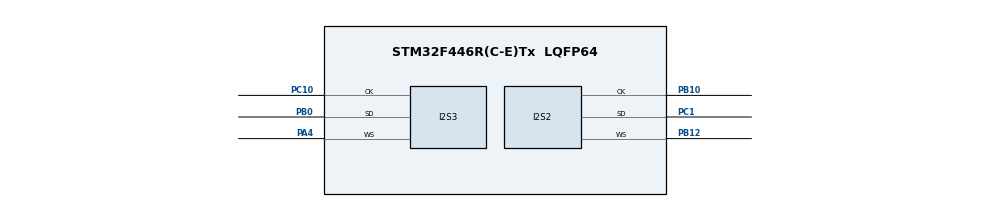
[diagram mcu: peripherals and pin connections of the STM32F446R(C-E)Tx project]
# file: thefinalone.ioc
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Dma.Request0=SPI2_TX
Dma.Request1=SPI3_RX
Dma.SPI2_TX.0.Direction=DMA_MEMORY_TO_PERIPH
Dma.SPI2_TX.0.FIFOMode=DMA_FIFOMODE_DISABLE
Dma.SPI2_TX.0.Instance=DMA1_Stream4
Dma.SPI2_TX.0.MemDataAlignment=DMA_MDATAALIGN_BYTE
Dma.SPI2_TX.0.MemInc=DMA_MINC_ENABLE
Dma.SPI2_TX.0.Mode=DMA_CIRCULAR
Dma.SPI2_TX.0.PeriphDataAlignment=DMA_PDATAALIGN_BYTE
Dma.SPI2_TX.0.PeriphInc=DMA_PINC_DISABLE
Dma.SPI2_TX.0.Priority=DMA_PRIORITY_HIGH
Dma.SPI3_RX.1.Direction=DMA_PERIPH_TO_MEMORY
Dma.SPI3_RX.1.FIFOMode=DMA_FIFOMODE_DISABLE
Dma.SPI3_RX.1.Instance=DMA1_Stream2
Dma.SPI3_RX.1.MemDataAlignment=DMA_MDATAALIGN_BYTE
Dma.SPI3_RX.1.MemInc=DMA_MINC_ENABLE
Dma.SPI3_RX.1.Mode=DMA_CIRCULAR
Dma.SPI3_RX.1.PeriphDataAlignment=DMA_PDATAALIGN_BYTE
Dma.SPI3_RX.1.PeriphInc=DMA_PINC_DISABLE
Dma.SPI3_RX.1.Priority=DMA_PRIORITY_HIGH
I2S2.AudioFreq=I2S_AUDIOFREQ_16K
I2S2.DataFormat=I2S_DATAFORMAT_24B
I2S2.ErrorAudioFreq=-0.26 %
I2S2.FullDuplexMode=I2S_FULLDUPLEXMODE_DISABLE
I2S2.Instance=SPI$Index
I2S2.RealAudioFreq=15.957 KHz
I2S2.Standard=I2S_STANDARD_PHILIPS
I2S2.VirtualMode=I2S_MODE_MASTER
I2S3.AudioFreq=I2S_AUDIOFREQ_16K
I2S3.ClockSource-Half_Duplex_Master=I2S_CLOCK_PLL
I2S3.DataFormat=I2S_DATAFORMAT_24B
I2S3.ErrorAudioFreq=-0.26 %
I2S3.FullDuplexMode=I2S_FULLDUPLEXMODE_DISABLE
I2S3.Instance=SPI$Index
I2S3.Mode=I2S_MODE_MASTER_RX
I2S3.RealAudioFreq=15.957 KHz
I2S3.Standard=I2S_STANDARD_PHILIPS
I2S3.VirtualMode=I2S_MODE_MASTER
Mcu.Family=STM32F4
Mcu.Name=STM32F446R(C-E)Tx
Mcu.Package=LQFP64
NVIC.DMA1_Stream2_IRQn=true\:0\:0\:false\:false\:true\:false\:true\:true
NVIC.DMA1_Stream4_IRQn=true\:0\:0\:false\:false\:true\:false\:true\:true
NVIC.PriorityGroup=NVIC_PRIORITYGROUP_4
PA0-WKUP.Signal=UART4_TX
PA1.Signal=UART4_RX
PA13.Mode=JTAG_5_pins
PA13.Signal=SYS_JTMS-SWDIO
PA14.Mode=JTAG_5_pins
PA14.Signal=SYS_JTCK-SWCLK
PA15.Mode=JTAG_5_pins
PA15.Signal=SYS_JTDI
PA4.Mode=Half_Duplex_Master
PA4.Signal=I2S3_WS
PB0.Mode=Half_Duplex_Master
PB0.Signal=I2S3_SD
PB10.Mode=Half_Duplex_Master
PB10.Signal=I2S2_CK
PB12.Mode=Half_Duplex_Master
PB12.Signal=I2S2_WS
PB3.Mode=JTAG_5_pins
PB3.Signal=SYS_JTDO-SWO
PB4.Mode=JTAG_5_pins
PB4.Signal=SYS_JTRST
PC1.Mode=Half_Duplex_Master
PC1.Signal=I2S2_SD
PC10.Mode=Half_Duplex_Master
PC10.Signal=I2S3_CK
ProjectManager.HeapSize=0x200
ProjectManager.StackSize=0x400
ProjectManager.TargetToolchain=STM32CubeIDE
RCC.CortexFreq_Value=16000000
RCC.HSE_VALUE=25000000
RCC.USBFreq_Value=96000000
RCC.VCOOutputFreq_Value=192000000
board=custom

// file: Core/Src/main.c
/* USER CODE BEGIN Header */
/**
  ******************************************************************************
  * @file           : main.c
  * @brief          : Main program body
  ******************************************************************************
  * @attention
  *
  * Copyright (c) 2024 STMicroelectronics.
  * All rights reserved.
  *
  * This software is licensed under terms that can be found in the LICENSE file
  * in the root directory of this software component.
  * If no LICENSE file comes with this software, it is provided AS-IS.
  *
  ******************************************************************************
  */
/* USER CODE END Header */
#include "main.h"

I2S_HandleTypeDef hi2s2;
I2S_HandleTypeDef hi2s3;
DMA_HandleTypeDef hdma_spi2_tx;
DMA_HandleTypeDef hdma_spi3_rx;

void SystemClock_Config(void);
void PeriphCommonClock_Config(void);
static void MX_GPIO_Init(void);
static void MX_DMA_Init(void);
static void MX_I2S2_Init(void);
static void MX_I2S3_Init(void);

/* USER CODE BEGIN 0 */
uint16_t rxBuf[8];
uint16_t txBuf[8];
//memset(rxBuf, 0, sizeof(rxBuf));
//memset(txBuf, 0, sizeof(txBuf));

/* USER CODE END 0 */

int main(void)
{
  /* USER CODE BEGIN 1 */
  __HAL_DBGMCU_UNFREEZE_IWDG();
  /* USER CODE END 1 */

  /* MCU Configuration--------------------------------------------------------*/

  /* Reset of all peripherals, Initializes the Flash interface and the Systick. */
  HAL_Init();

  /* Configure the system clock */
  SystemClock_Config();

/* Configure the peripherals common clocks */
  PeriphCommonClock_Config();

  /* Initialize all configured peripherals */
  MX_GPIO_Init();
  MX_DMA_Init();
  MX_I2S2_Init();
  MX_I2S3_Init();
  /* USER CODE BEGIN 2 */
  volatile int32_t data[4];
  HAL_I2S_Receive_DMA(&hi2s3, data, sizeof(data)/sizeof(*data));
  HAL_I2S_Transmit_DMA(&hi2s2, data, sizeof(data)/sizeof(*data));
  //HAL_I2S_Receive_DMA(&hi2s3, rxBuf, 4);
  //HAL_I2S_Transmit_DMA(&hi2s2, rxBuf, 4);
  //HAL_I2S_Receive_DMA(&hi2s3, txBuf, 4);
  /* USER CODE END 2 */

  /* Infinite loop */
  while (1)
  {

  }
}

void SystemClock_Config(void)
{
  RCC_OscInitTypeDef RCC_OscInitStruct = {0};
  RCC_ClkInitTypeDef RCC_ClkInitStruct = {0};

  /** Macro to configure the PLL multiplication factor
  */
  __HAL_RCC_PLL_PLLM_CONFIG(16);

  /** Macro to configure the PLL clock source
  */
  __HAL_RCC_PLL_PLLSOURCE_CONFIG(RCC_PLLSOURCE_HSI);

  /** Configure the main internal regulator output voltage
  */
  __HAL_RCC_PWR_CLK_ENABLE();
  __HAL_PWR_VOLTAGESCALING_CONFIG(PWR_REGULATOR_VOLTAGE_SCALE3);

  /** Initializes the RCC Oscillators according to the specified parameters
  * in the RCC_OscInitTypeDef structure.
  */
  RCC_OscInitStruct.OscillatorType = RCC_OSCILLATORTYPE_HSI;
  RCC_OscInitStruct.HSIState = RCC_HSI_ON;
  RCC_OscInitStruct.HSICalibrationValue = RCC_HSICALIBRATION_DEFAULT;
  RCC_OscInitStruct.PLL.PLLState = RCC_PLL_NONE;
  RCC_OscInitStruct.PLL.PLLSource = RCC_PLLSOURCE_HSI;
  if (HAL_RCC_OscConfig(&RCC_OscInitStruct) != HAL_OK)
  {
    Error_Handler();
  }

  /** Initializes the CPU, AHB and APB buses clocks
  */
  RCC_ClkInitStruct.ClockType = RCC_CLOCKTYPE_HCLK|RCC_CLOCKTYPE_SYSCLK
                              |RCC_CLOCKTYPE_PCLK1|RCC_CLOCKTYPE_PCLK2;
  RCC_ClkInitStruct.SYSCLKSource = RCC_SYSCLKSOURCE_HSI;
  RCC_ClkInitStruct.AHBCLKDivider = RCC_SYSCLK_DIV1;
  RCC_ClkInitStruct.APB1CLKDivider = RCC_HCLK_DIV1;
  RCC_ClkInitStruct.APB2CLKDivider = RCC_HCLK_DIV1;

  if (HAL_RCC_ClockConfig(&RCC_ClkInitStruct, FLASH_LATENCY_0) != HAL_OK)
  {
    Error_Handler();
  }
}

void PeriphCommonClock_Config(void)
{
  RCC_PeriphCLKInitTypeDef PeriphClkInitStruct = {0};

  /** Initializes the peripherals clock
  */
  PeriphClkInitStruct.PeriphClockSelection = RCC_PERIPHCLK_I2S_APB1;
  PeriphClkInitStruct.PLLI2S.PLLI2SN = 192;
  PeriphClkInitStruct.PLLI2S.PLLI2SP = RCC_PLLI2SP_DIV2;
  PeriphClkInitStruct.PLLI2S.PLLI2SM = 16;
  PeriphClkInitStruct.PLLI2S.PLLI2SR = 2;
  PeriphClkInitStruct.PLLI2S.PLLI2SQ = 2;
  PeriphClkInitStruct.PLLI2SDivQ = 1;
  PeriphClkInitStruct.I2sApb1ClockSelection = RCC_I2SAPB1CLKSOURCE_PLLI2S;
  if (HAL_RCCEx_PeriphCLKConfig(&PeriphClkInitStruct) != HAL_OK)
  {
    Error_Handler();
  }
}

static void MX_I2S2_Init(void)
{

  hi2s2.Instance = SPI2;
  hi2s2.Init.Mode = I2S_MODE_MASTER_TX;
  hi2s2.Init.Standard = I2S_STANDARD_PHILIPS;
  hi2s2.Init.DataFormat = I2S_DATAFORMAT_24B;
  hi2s2.Init.MCLKOutput = I2S_MCLKOUTPUT_DISABLE;
  hi2s2.Init.AudioFreq = I2S_AUDIOFREQ_8K;
  hi2s2.Init.CPOL = I2S_CPOL_LOW;
  hi2s2.Init.ClockSource = I2S_CLOCK_PLL;
  hi2s2.Init.FullDuplexMode = I2S_FULLDUPLEXMODE_DISABLE;
  if (HAL_I2S_Init(&hi2s2) != HAL_OK)
  {
    Error_Handler();
  }

}

static void MX_I2S3_Init(void)
{

  hi2s3.Instance = SPI3;
  hi2s3.Init.Mode = I2S_MODE_MASTER_RX;
  hi2s3.Init.Standard = I2S_STANDARD_PHILIPS;
  hi2s3.Init.DataFormat = I2S_DATAFORMAT_24B;
  hi2s3.Init.MCLKOutput = I2S_MCLKOUTPUT_DISABLE;
  hi2s3.Init.AudioFreq = I2S_AUDIOFREQ_8K;
  hi2s3.Init.CPOL = I2S_CPOL_LOW;
  hi2s3.Init.ClockSource = I2S_CLOCK_PLL;
  hi2s3.Init.FullDuplexMode = I2S_FULLDUPLEXMODE_DISABLE;
  if (HAL_I2S_Init(&hi2s3) != HAL_OK)
  {
    Error_Handler();
  }

}

static void MX_DMA_Init(void)
{

  /* DMA controller clock enable */
  __HAL_RCC_DMA1_CLK_ENABLE();

  /* DMA interrupt init */
  /* DMA1_Stream0_IRQn interrupt configuration */
  HAL_NVIC_SetPriority(DMA1_Stream0_IRQn, 0, 0);
  HAL_NVIC_EnableIRQ(DMA1_Stream0_IRQn);
  /* DMA1_Stream4_IRQn interrupt configuration */
  HAL_NVIC_SetPriority(DMA1_Stream4_IRQn, 0, 0);
  HAL_NVIC_EnableIRQ(DMA1_Stream4_IRQn);

}

static void MX_GPIO_Init(void)
{

  /* GPIO Ports Clock Enable */
  __HAL_RCC_GPIOC_CLK_ENABLE();
  __HAL_RCC_GPIOA_CLK_ENABLE();
  __HAL_RCC_GPIOB_CLK_ENABLE();

}

/* USER CODE BEGIN 4 */

void HAL_I2S_TxHalfCpltCallback(I2S_HandleTypeDef *hi2s){
/*
	//restore signed 24 bit sample from 16-bit buffers
	int lSample = (int) (rxBuf[0]<<16)|rxBuf[1];
	int rSample = (int) (rxBuf[2]<<16)|rxBuf[3];

	// divide by 2 (rightshift) -> -3dB per sample
	lSample = lSample>>1;
	rSample = rSample>>1;

	//sum to mono
	lSample = rSample + lSample;
	rSample = lSample;

	//restore to buffer
	txBuf[0] = (lSample>>16)&0xFFFF;
	txBuf[1] = lSample&0xFFFF;
	txBuf[2] = (rSample>>16)&0xFFFF;
	txBuf[3] = rSample&0xFFFF;*/
	for(int i = 0; i < 4; i++){
		txBuf[i] = rxBuf[i];
	}
}

void HAL_I2S_TxCpltCallback(I2S_HandleTypeDef *hi2s){
	/*
	//restore signed 24 bit sample from 16-bit buffers
	int lSample = (int) (rxBuf[4]<<16)|rxBuf[5];
	int rSample = (int) (rxBuf[6]<<16)|rxBuf[7];

	// divide by 2 (rightshift) -> -3dB per sample
	lSample = lSample>>1;
	rSample = rSample>>1;

	//sum to mono
	lSample = rSample + lSample;
	rSample = lSample;

	//restore to buffer
	txBuf[4] = (lSample>>16)&0xFFFF;
	txBuf[5] = lSample&0xFFFF;
	txBuf[6] = (rSample>>16)&0xFFFF;
	txBuf[7] = rSample&0xFFFF;
	/*

	 */
	for(int i = 4; i < 8; i++){
		txBuf[i] = rxBuf[i];
	}
}

/* USER CODE END 4 */

void Error_Handler(void)
{
  __disable_irq();
  while (1)
  {
  }
}
